# D1H.pdf register map
Vendor: Allwinner; Series: D1H.pdf; File version: 0.1
CPU: XuanTie C906 RISC-V CPU 0, little endian, MPU, FPU, double-precision FPU, 0 interrupt priority bits
Registers are 32-bit, read-write, reset 0x0 unless marked. A register's access mark holds for its fields unless they carry their own. Offsets are from the block's base; [hi:lo] are bit positions; lines under a group give offsets from that group; {n}, {i} and the like mark numbered series; 'fields as' and 'values as' point back to an identical list.

## EMAC
Base 0x04500000
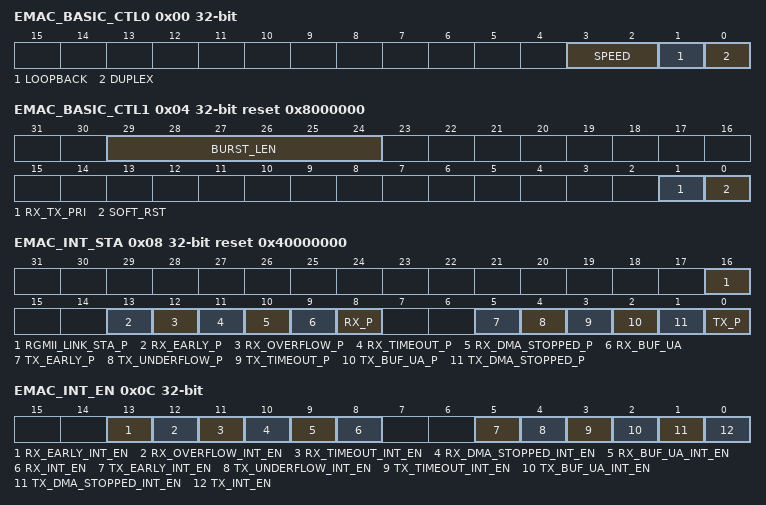
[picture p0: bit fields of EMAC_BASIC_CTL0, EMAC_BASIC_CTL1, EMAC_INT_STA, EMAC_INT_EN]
0x00 EMAC_BASIC_CTL0 — EMAC Basic Control Register0
  [3:2] SPEED — EMAC Working Speed 00: 1000 Mbit/s 01: Reserved 10: 10 Mbit/s 11: 100 Mbit/s
    0=1000 Mbit/s; 2=10 Mbit/s; 3=100 Mbit/s
  [1] LOOPBACK — EMAC Loopback Mode For Test 0: Disable 1: Enable
    0=Disable; 1=Enable
  [0] DUPLEX — EMAC Transfer Mode 0: Half-duplex 1: Full-duplex
    0=half_duplex; 1=full_duplex
0x04 EMAC_BASIC_CTL1 reset 0x8000000 — EMAC Basic Control Register1
  [29:24] BURST_LEN — The burst length of RX and TX DMA transfer.
  [1] RX_TX_PRI — RX TX DMA Priority 0: Same priority 1: RX priority is over TX
    0=Same priority; 1=RX (RX priority is over TX)
  [0] SOFT_RST — Soft Reset all Registers and Logic 0: No valid 1: Reset All clock inputs must be valid before soft reset. This bit is cleared internally when the reset operation is completed fully. Before writing any register, this bit should read a 0.
    0=No_valid; 1=Reset All clock inputs must be valid before soft reset. This bit is cleared internally when the reset operation is completed fully. Before writing any register, this bit should read a 0.
0x08 EMAC_INT_STA reset 0x40000000 — EMAC Interrupt Status Register
  [16] RGMII_LINK_STA_P write-1-clears — RMII Link Status Changed Interrupt Pending 0: No Pending 1: Pending Write ‘1’ to clear it.
    0=No_Pending; 1=Pending Write ‘1’ to clear it
  [13] RX_EARLY_P write-1-clears — RX DMA Filled First Data Buffer of the Receive Frame Interrupt Pending 0: No Pending 1: Pending Write ‘1’ to clear it.
    0=No_Pending; 1=Pending Write ‘1’ to clear it
  [12] RX_OVERFLOW_P write-1-clears — RX FIFO Overflow Error Interrupt Pending 0: No Pending 1: Pending Write ‘1’ to clear it.
    0=No_Pending; 1=Pending Write ‘1’ to clear it
  [11] RX_TIMEOUT_P write-1-clears — RX Timeout Interrupt Pending 0: No Pending 1: Pending Write ‘1’ to clear it. When this bit is asserted, the length of the received frame is greater than 2048 bytes (10240 when JUMBO_FRM_EN is set)
    0=No_Pending; 1=Pending Write ‘1’ to clear it. When this bit is asserted, the length of the received frame is greater than 2048 bytes (10240 when JUMBO_FRM_EN is set)
  [10] RX_DMA_STOPPED_P write-1-clears — When this bit asserted, the RX DMA FSM is stopped.
  [9] RX_BUF_UA write-1-clears — _P RX Buffer UA Interrupt Pending 0: No Pending 1: Pending Write ‘1’ to clear it. When this bit is asserted, the RX DMA cannot acquire the next RX descriptor and RX DMA FSM is suspended. The ownership of the next RX descriptor should be changed to RX DMA. The RX DMA FSM will resume when the RX_DMA_START is written or the next receive frame is coming.
    0=No_Pending; 1=Pending Write ‘1’ to clear it. When this bit is asserted, the RX DMA cannot acquire the next RX descriptor and RX DMA FSM is suspended. The ownership of the next RX descriptor should be changed to RX DMA. The RX DMA FSM will resume when the RX_DMA_START is written or the next receive frame is coming.
  [8] RX_P write-1-clears — Frame RX Completed Interrupt Pending 0: No Pending 1: Pending Write ‘1’ to clear it. When this bit is asserted, a frame reception is completed. The RX DMA FSM remains running.
    0=No_Pending; 1=Pending Write ‘1’ to clear it. When this bit is asserted, a frame reception is completed. The RX DMA FSM remains running.
  [5] TX_EARLY_P write-1-clears — Total interrupt pending which the frame is transmitted to FIFO 0: No Pending 1: Pending Write ‘1’ to clear it.
    0=No_Pending; 1=Pending Write ‘1’ to clear it
  [4] TX_UNDERFLOW_P write-1-clears — TX FIFO Underflow Interrupt Pending 0: No Pending 1: Pending Write ‘1’ to clear it.
    0=No_Pending; 1=Pending Write ‘1’ to clear it
  [3] TX_TIMEOUT_P write-1-clears — Transmitter Timeout Interrupt Pending 0: No Pending 1: Pending Write ‘1’ to clear it.
    0=No_Pending; 1=Pending Write ‘1’ to clear it
  [2] TX_BUF_UA_P write-1-clears — TX Buffer UA Interrupt Pending 0: No Pending 1: Pending When this asserted, the TX DMA can not acquire the next TX descriptor and the TX DMA FSM is suspended. The ownership of the next TX descriptor should be changed to TX DMA. The TX DMA FSM will resume when writing to TX_DMA_START bit.
    0=No_Pending; 1=Pending When this asserted, the TX DMA can not acquire the next TX descriptor and the TX DMA FSM is suspended. The ownership of the next TX descriptor should be changed to TX DMA. The TX DMA FSM will resume when writing to TX_DMA_START bit.
  [1] TX_DMA_STOPPED_P write-1-clears — Transmission DMA Stopped Interrupt Pending 0: No Pending 1: Pending Write ‘1’ to clear it.
    0=No_Pending; 1=Pending Write ‘1’ to clear it
  [0] TX_P write-1-clears — Frame Transmission Interrupt Pending 0: No Pending 1: Pending Write ‘1’ to clear it.
    0=No_Pending; 1=Pending Write ‘1’ to clear it
0x0C EMAC_INT_EN — EMAC Interrupt Enable Register
  [all] fields
    0=Disable; 1=Enable
  [13] RX_EARLY_INT_EN — Early Receive Interrupt 0: Disable 1: Enable
  [12] RX_OVERFLOW_INT_EN — Receive Overflow Interrupt 0: Disable 1: Enable
  [11] RX_TIMEOUT_INT_EN — Receive Timeout Interrupt 0: Disable 1: Enable
  [10] RX_DMA_STOPPED_INT_EN — Receive DMA FSM Stopped Interrupt 0: Disable 1: Enable
  [9] RX_BUF_UA_INT_EN — Receive Buffer Unavailable Interrupt 0: Disable 1: Enable
  [8] RX_INT_EN — Receive Interrupt 0: Disable 1: Enable
  [5] TX_EARLY_INT_EN — Early Transmit Interrupt 0: Disable 1: Enable
  [4] TX_UNDERFLOW_INT_EN — Transmit Underflow Interrupt 0: Disable 1: Enable
  [3] TX_TIMEOUT_INT_EN — Transmit Timeout Interrupt 0: Disable 1: Enable
  [2] TX_BUF_UA_INT_EN — Transmit Buffer Available Interrupt 0: Disable 1: Enable
  [1] TX_DMA_STOPPED_INT_EN — Transmit DMA FSM Stopped Interrupt 0: Disable 1: Enable
  [0] TX_INT_EN — Transmit Interrupt 0: Disable 1: Enable
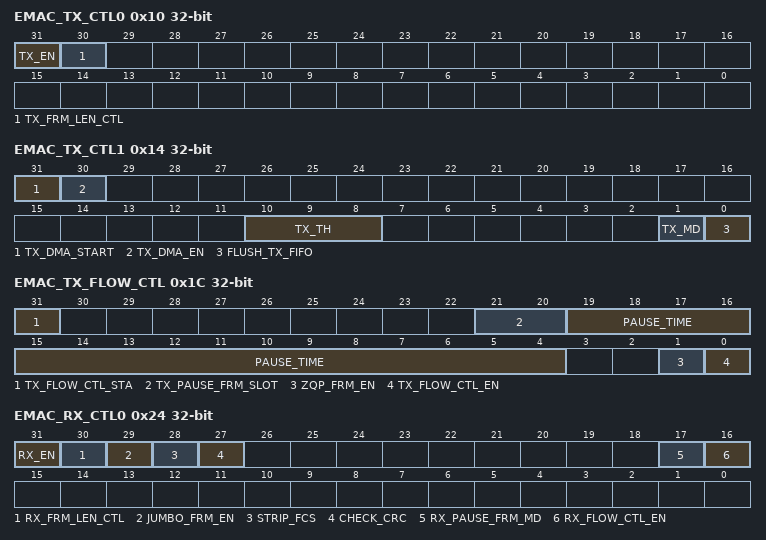
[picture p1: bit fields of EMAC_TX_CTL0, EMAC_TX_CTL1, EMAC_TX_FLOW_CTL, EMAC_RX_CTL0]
0x10 EMAC_TX_CTL0 — EMAC Transmit Control Register0
  [31] TX_EN — Enable Transmitter 0: Disable 1: Enable When disabled, the transmission will continue until the current transmission finishes.
    0=Disable; 1=Enable When disabled, the transmission will continue until the current transmission finishes
  [30] TX_FRM_LEN_CTL — Frame Transmit Length Control 0: Up to 2,048 bytes (JUMBO_FRM_EN==0) Up to 10,240 bytes (JUMBO_FRM_EN==1) 1: Up to 16,384 bytes Any bytes after that is cut off.
    0=Up_to_2_comma_048 (Up to 2,048 bytes (JUMBO_FRM_EN==0) Up to 10,240 bytes (JUMBO_FRM_EN==1)); 1=Up_to_16_comma_384 (Up to 16,384 bytes Any bytes after that is cut off.)
0x14 EMAC_TX_CTL1 — EMAC Transmit Control Register1
  [31] TX_DMA_START — Transmit DMA FSM Start 0: No valid 1: Start It is cleared internally and always read a 0.
    0=No_valid; 1=Start It is cleared internally and always read a 0
  [30] TX_DMA_EN — 0: Stop TX DMA after the completion of current frame transmission 1: Start and run TX DMA
    0=Stop TX DMA after the completion of current frame transmission; 1=Start and run TX DMA
  [10:8] TX_TH — Threshold value of TX DMA FIFO When TX_MD is 0, the transmission starts when the frame size in TX DMA FIFO is greater than the threshold. In addition, the full frames with a length less than the threshold are transferred automatically. 000: 64 001: 128 010: 192 011: 256 Others: Reserved
    0=_64; 1=_128; 2=_192; 3=_256
  [1] TX_MD — Transmission Mode 0: TX starts after the TX DMA FIFO bytes is greater than the TX_TH 1: TX starts after the TX DMA FIFO is located a full frame
    0=TX starts after the TX DMA FIFO bytes is greater than the TX_TH; 1=located (TX starts after the TX DMA FIFO is located a full frame)
  [0] FLUSH_TX_FIFO — Flush the data in the TX FIFO 0: Enable 1: Disable
    0=Enable; 1=Disable
0x1C EMAC_TX_FLOW_CTL — EMAC Transmit Flow Control Register
  [31] TX_FLOW_CTL_STA — This bit indicates a pause frame transmission is in progress. When the configuration of flow control is ready, set this bit to transmit a pause frame in full-duplex mode or activate the backpressure function. After the transmission is completed, this bit will be cleared automatically. Before writing TX_FLOW_CTRL register, this bit must be read as 0.
  [21:20] TX_PAUSE_FRM_SLOT — The threshold of the pause timer at which the input flow control signal is checked for automatic re-transmission of the pause frame. The threshold values should be always less than PAUSE_TIME.
  [19:4] PAUSE_TIME — The pause time field in the transmitted control frame.
  [1] ZQP_FRM_EN — 0: Disable 1: Enable When set, enable the functionality to generate the Zero-Quanta Pause control frame.
    0=Disable; 1=Enable When set, enable the functionality to generate the Zero-Quanta Pause control frame
  [0] TX_FLOW_CTL_EN — TX Flow Control Enable 0: Disable 1: Enable When set, enable flow control operation to transmit pause frames in full-duplex mode, or enable the back-pressure operation in half- duplex mode.
    0=Disable; 1=Enable When set, enable flow control operation to transmit pause frames in full-duplex mode, or enable the back-pressure operation in half- duplex mode
0x20 EMAC_TX_DMA_LIST
  [31:0] TX_DESC_LIST — The base address of the transmission descriptor list It must be 32-bit aligned.
0x24 EMAC_RX_CTL0 — EMAC Receive Control Register0
  [31] RX_EN — Enable Receiver 0: Disable receiver after current reception 1: Enable
    0=Disable receiver after current reception; 1=Enable
  [30] RX_FRM_LEN_CTL — Frame Receive Length Control 0: Up to 2048 bytes (JUMBO_FRM_EN==0) Up to 10240 bytes (JUMBO_FRM_EN==1) 1: Up to 16384 bytes Any bytes after that is cut off.
    0=Up to 2048 bytes (JUMBO_FRM_EN==0) Up to 10240 bytes (JUMBO_FRM_EN==1); 1=Up to 16384 bytes Any bytes after that is cut off
  [29] JUMBO_FRM_EN — Jumbo Frame Enable 0: Disable 1: Enable Jumbo frames of 9018 bytes without reporting a giant
    0=Disable; 1=Enable Jumbo frames of 9018 bytes without reporting a giant
  [28] STRIP_FCS — When set, strip the Pad/FCS field on received frames only when the length of field value is less than or equal to 1500 bytes.
  [27] CHECK_CRC — Check CRC Enable 0: Disable 1: Calculate CRC and check the IPv4 Header Checksum
    0=Disable; 1=Calculate CRC and check the IPv4 Header Checksum
  [17] RX_PAUSE_FRM_MD — 0: Only detect multicast pause frame specified in the 802.3x standard. 1: In addition to detect multicast pause frame specified in the 802.3x standard, also detect unicast pause frame with the address specified in MAC Address 0 High Register and MAC address 0 Low Register.
    0=Only detect multicast pause frame specified in the 802.3x standard; 1=In (In addition to detect multicast pause frame specified in the 802.3x standard, also detect unicast pause frame with the address specified in MAC Address 0 High Register and MAC address 0 Low Register.)
  [16] RX_FLOW_CTL_EN — When set, enable the functionality that decodes the received pause frame and disable its transmitter for a specified time by pause frame.
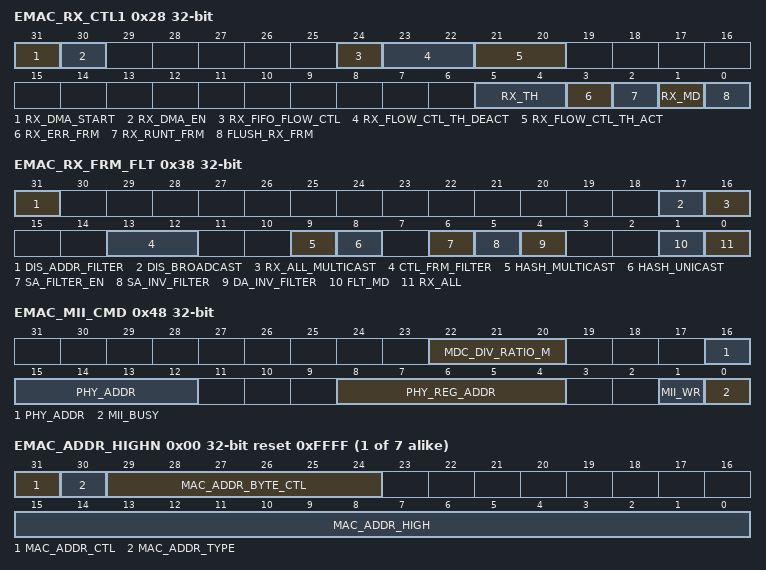
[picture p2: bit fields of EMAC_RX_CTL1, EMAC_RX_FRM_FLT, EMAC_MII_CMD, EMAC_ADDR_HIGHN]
0x28 EMAC_RX_CTL1 — EMAC Receive Control Register1
  [31] RX_DMA_START — When set, the RX DMA will work. It is cleared internally and always read a 0.
  [30] RX_DMA_EN — Receive DMA Enable 0: Stop RX DMA after finishing the received current frame 1: Start and run RX DMA
    0=Stop RX DMA after finishing the received current frame; 1=Start and run RX DMA
  [24] RX_FIFO_FLOW_CTL — Receive FIFO Flow Control Enable 0: Disable 1: Enable, base on RX_FLOW_CTL_TH_DEACT and RX_FLOW_CTL_TH_ACT
    0=Disable; 1=Enable, base on RX_FLOW_CTL_TH_DEACT and RX_FLOW_CTL_TH_ACT
  [23:22] RX_FLOW_CTL_TH_DEACT — Threshold for Deactivating Flow Control 00: Full minus 1 KB 01: Full minus 2 KB 10: Full minus 3 KB 11: Full minus 4 KB Valid in both half-duplex mode and full-duplex mode.
    0=Full minus 1 KB; 1=Full minus 2 KB; 2=Full minus 3 KB; 3=Full minus 4 KB Valid in both half-duplex mode and full-duplex mode
  [21:20] RX_FLOW_CTL_TH_ACT — Threshold for Activating Flow Control 00: Full minus 1 KB 01: Full minus 2 KB 10: Full minus 3 KB 11: Full minus 4 KB Valid in both half-duplex mode and full-duplex mode.
    values as RX_FLOW_CTL_TH_DEACT
  [5:4] RX_TH — Threshold for RX DMA FIFO Start 00: 64 01: 32 10: 96 11: 128 Only valid when RX_MD == 0, the full frames with a length less than the threshold are transferred automatically.
    0=_64; 1=_32; 2=_96; 3=128 Only valid when RX_MD == 0, the full frames with a length less than the threshold are transferred automatically
  [3] RX_ERR_FRM — 0: RX DMA drops frames with error 1: RX DMA forwards frames with error
    0=RX DMA drops frames with error; 1=RX DMA forwards frames with error
  [2] RX_RUNT_FRM — When the bit is set to 1, it indicates forward undersized frames with no error and length less than 64 bytes.
  [1] RX_MD — Receive Mode 0: RX starts to read after the RX DMA FIFO byte is greater than RX_TH 1: RX starts to read after the RX DMA FIFO is located a full frame
    0=RX starts to read after the RX DMA FIFO byte is greater than RX_TH; 1=located (RX starts to read after the RX DMA FIFO is located a full frame)
  [0] FLUSH_RX_FRM — Flush Receive Frames 0: Enable when the receive descriptors/buffers are unavailable 1: Disable
    0=Enable when the receive descriptors/buffers are unavailable; 1=Disable
0x34 EMAC_RX_DMA_LIST
  [31:0] RX_DESC_LIST — The base address of the received descriptor list It must be 32-bit aligned.
0x38 EMAC_RX_FRM_FLT — EMAC Receive Frame Filter Register
  [31] DIS_ADDR_FILTER — Disable Address Filter 0: Enable 1: Disable
    0=Enable; 1=Disable
  [17] DIS_BROADCAST — Disable Receive Broadcast Frames 0: Receive 1: Drop
    0=Receive; 1=Drop
  [16] RX_ALL_MULTICAST — Receive All Multicast Frames Filter 0: Filter according to HASH_MULTICAST 1: Receive all
    0=Filter according to HASH_MULTICAST; 1=Receive all
  [13:12] CTL_FRM_FILTER — Receive Control Frames Filter 00: Drop all control frames 01: Drop all control frames 10: Receive all control frames 11: Receive all control frames when passing the address filter
  [9] HASH_MULTICAST — Filter Multicast Frames Set 0: By comparing the DA field in DA MAC address registers 1: According to the hash table
    0=By (By comparing the DA field in DA MAC address registers); 1=According to the hash table
  [8] HASH_UNICAST — Filter Unicast Frames Set 0: By comparing the DA field in DA MAC address registers 1: According to the hash table
    values as HASH_MULTICAST
  [6] SA_FILTER_EN — Receive SA Filter Enable 0: Receive frames and update the result of SA filter 1: Update the result of the SA filter. In addition, if the SA field of the received frame does not match the values in SA MAC address registers, drop this frame.
    0=Receive frames and update the result of SA filter; 1=Update the result of the SA filter. In addition, if the SA field of the received frame does not match the values in SA MAC address registers, drop this frame.
  [5] SA_INV_FILTER — Receive SA Invert Filter Set 0: Pass frames whose SA field matches SA MAC address registers 1: Pass frames whose SA field does not match SA MAC address registers
    0=Pass frames whose SA field matches SA MAC address registers; 1=Pass frames whose SA field does not match SA MAC address registers
  [4] DA_INV_FILTER — 0: Normal filtering of frames is performed 1: Filter both unicast and multicast frames by comparing DA field in inverse filtering mode
    0=Normal filtering of frames is performed; 1=Filter both unicast and multicast frames by comparing DA field in inverse filtering mode
  [1] FLT_MD — 0: If the HASH_MULTICAST or HASH_UNICAST is set, the frame is passed only when it matches the Hash filter 1: Receive the frame when it passes the address register filter or the hash filter (set by HASH_MULTICAST or HASH_UNICAST)
    0=If (If the HASH_MULTICAST or HASH_UNICAST is set, the frame is passed only when it matches the Hash filter); 1=Receive the frame when it passes the address register filter or the hash filter (set by HASH_MULTICAST or HASH_UNICAST)
  [0] RX_ALL — Receive All Frame 0: Receive the frames that pass the SA/DA address filter 1: Receive all frames and update the result of address filter (pass or fail) in the receive status word
    0=Receive the frames that pass the SA/DA address filter; 1=Receive all frames and update the result of address filter (pass or fail) in the receive status word
0x40 EMAC_RX_HASH0 — EMAC Hash Table Register0
  [31:0] HASH_TAB0 — The upper 32 bits of Hash table for the received frame filter.
0x44 EMAC_RX_HASH1 — EMAC Hash Table Register1
  [31:0] HASH_TAB1 — The lower 32 bits of Hash table for the received frame filter.
0x48 EMAC_MII_CMD — EMAC Management Interface Command Register
  [22:20] MDC_DIV_RATIO_M — MDC Clock Divider Ratio The MDC Clock is divided from the AHB clock. 000: 16 001: 32 010: 64 011: 128 Others: Reserved
    0=_16; 1=_32; 2=_64; 3=_128
  [16:12] PHY_ADDR — PHY Address
  [8:4] PHY_REG_ADDR — PHY Register Address
  [1] MII_WR — MII Write and Read 0: Read 1: Write
    0=Read; 1=Write
  [0] MII_BUSY — MII Status 0: Writing 0 is no valid, and reading 0 indicates the read/write operation is finished 1: Writing 1 starts the read/write operation, and reading 1 indicates busy.
    0=Writing 0 is no valid, and reading 0 indicates the read/write operation is finished; 1=Writing 1 starts the read/write operation, and reading 1 indicates busy
0x4C EMAC_MII_DATA — EMAC Management Interface Data Register
  [15:0] MII_DATA — Write to or read from the register in the selected PHY.
0x50 EMAC_ADDR_HIGH0 reset 0xFFFF — EMAC MAC Address High Register0
  [15:0] MAC_ADDR_HIGH0 — The upper 16 bits of the 1st MAC address.
0x54 EMAC_ADDR_LOW0 reset 0xFFFFFFFF — EMAC MAC Address Low Register0
  [31:0] MAC_ADDR_LOW0 — The lower 32 bits of 1st MAC address.
{0x50+8i} _N_{i} (i=1..7) group
  0x00 EMAC_ADDR_HIGHN reset 0xFFFF — (N=1–7) EMAC MAC Address High Register N (N=1–7)
    [31] MAC_ADDR_CTL — MAC Address Valid 0: Not valid 1: Valid
      0=Not_valid; 1=Valid
    [30] MAC_ADDR_TYPE — MAC Address Type 0: Used to compare with the destination address of the received frame 1: Used to compare with the source address of the received frame
      0=Used to compare with the destination address of the received frame; 1=Used to compare with the source address of the received frame
    [29:24] MAC_ADDR_BYTE_CTL — MAC Address Byte Control Mask The lower bit of mask controls the lower byte of the MAC address. When the bit of mask is 1, do not compare the corresponding byte.
    [15:0] MAC_ADDR_HIGH — The upper 16 bits of the MAC address.
  0x04 EMAC_ADDR_LOWN — (N=1–7) EMAC MAC Address Low Register N (N=1–7)
    [31:0] MAC_ADDR_LOWN — The lower 32 bits of MAC address N (N: 1–7).
0xB0 EMAC_TX_DMA_STA — EMAC Transmit DMA Status Register
  [2:0] TX_DMA_STA ro — The State of Transmit DMA FSM 000: STOP, when reset or disable TX DMA 001: RUN_FETCH_DESC, fetching TX DMA descriptor 010: RUN_WAIT_STA, waiting for the status of TX frame 011: RUN_TRANS_DATA, passing the frame from host memory to TX DMA FIFO 100: Reserved 101: Reserved 111: RUN_CLOSE_DESC, closing TX descriptor 110: SUSPEND, TX descriptor is unavailable or TX DMA FIFO underflow
    0=STOP (STOP, when reset or disable TX DMA); 1=RUN_FETCH_DESC (RUN_FETCH_DESC, fetching TX DMA descriptor); 2=RUN_WAIT_STA (RUN_WAIT_STA, waiting for the status of TX frame); 3=RUN_TRANS_DATA (RUN_TRANS_DATA, passing the frame from host memory to TX DMA FIFO); 7=RUN_CLOSE_DESC (RUN_CLOSE_DESC, closing TX descriptor); 6=SUSPEND (SUSPEND, TX descriptor is unavailable or TX DMA FIFO underflow)
0xB4 EMAC_TX_DMA_CUR_DESC
  [31:0] TX_DMA_CUR_DESC ro — The address of current transmit descriptor.
0xB8 EMAC_TX_DMA_CUR_BUF
  [31:0] TX_DMA_CUR_BUF ro — The address of current transmit DMA buffer.
0xC0 EMAC_RX_DMA_STA — EMAC Receive DMA Status Register
  [2:0] RX_DMA_STA ro — The State of RX DMA FSM 000: STOP, when reset or disable RX DMA 001: RUN_FETCH_DESC, fetching RX DMA descriptor 010: Reserved 011: RUN_WAIT_FRM, waiting for the frame 100: SUSPEND, RX descriptor is unavailable 101: RUN_CLOSE_DESC, closing RX descriptor 110: Reserved 111: RUN_TRANS_DATA, passing the frame from host memory to RX DMA FIFO
    0=STOP (STOP, when reset or disable RX DMA); 1=RUN_FETCH_DESC (RUN_FETCH_DESC, fetching RX DMA descriptor); 3=RUN_WAIT_FRM (RUN_WAIT_FRM, waiting for the frame); 4=SUSPEND (SUSPEND, RX descriptor is unavailable); 5=RUN_CLOSE_DESC (RUN_CLOSE_DESC, closing RX descriptor); 7=RUN_TRANS_DATA (RUN_TRANS_DATA, passing the frame from host memory to RX DMA FIFO)
0xC4 EMAC_RX_DMA_CUR_DESC
  [31:0] RX_DMA_CUR_DESC ro — The address of current receive descriptor
0xC8 EMAC_RX_DMA_CUR_BUF
  [31:0] RX_DMA_CUR_BUF ro — The address of current receive DMA buffer
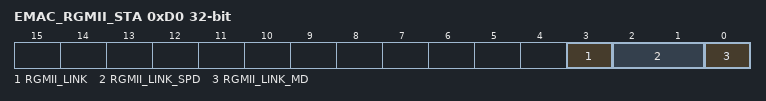
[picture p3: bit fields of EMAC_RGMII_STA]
0xD0 EMAC_RGMII_STA — EMAC RGMII Status Register
  [3] RGMII_LINK ro — The link status of the RGMII interface 0: Down 1: Up
    0=Down; 1=Up
  [2:1] RGMII_LINK_SPD ro — The link speed of the RGMII interface 00: 2.5 MHz 01: 25 MHz 10: 125 MHz 11: Reserved
    0=_2_point_5 (2.5 MHz); 1=25 MHz; 2=125 MHz
  [0] RGMII_LINK_MD ro — The link mode of the RGMII interface 0: Half-Duplex 1: Full-Duplex
    0=half_Duplex; 1=full_Duplex
